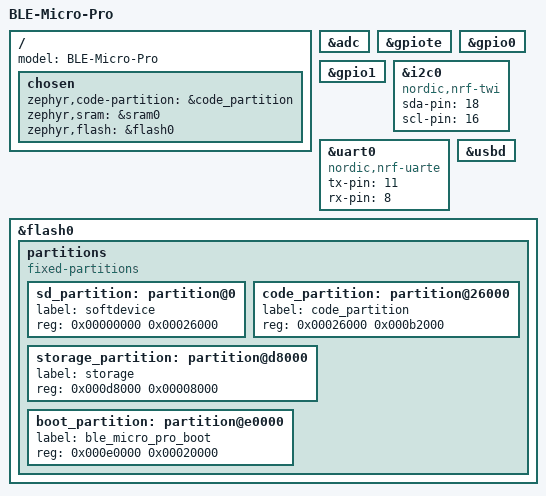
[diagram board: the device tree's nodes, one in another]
/*
 * Copyright (c) 2021 The ZMK Contributors
 *
 * SPDX-License-Identifier: MIT
 */

#include <nordic/nrf52840_qiaa.dtsi>
#include "arduino_pro_micro_pins.dtsi"

/ {
        model = "BLE-Micro-Pro";

        chosen {
                zephyr,code-partition = &code_partition;
                zephyr,sram = &sram0;
                zephyr,flash = &flash0;
        };
};

&adc {
        status = "okay";
};

&gpiote {
        status = "okay";
};

&gpio0 {
        status = "okay";
};

&gpio1 {
        status = "okay";
};

&i2c0 {
        compatible = "nordic,nrf-twi";
        sda-pin = <18>;
        scl-pin = <16>;
};

&uart0 {
        compatible = "nordic,nrf-uarte";
        tx-pin = <11>;
        rx-pin = <8>;
};

&usbd {
        status = "okay";
};

&flash0 {
        /*
         * For more information, see:
         * http://docs.zephyrproject.org/latest/devices/dts/flash_partitions.html
         */
        partitions {
                compatible = "fixed-partitions";
                #address-cells = <1>;
                #size-cells = <1>;

                sd_partition: partition@0 {
                        label = "softdevice";
                        reg = <0x00000000 0x00026000>;
                };
                code_partition: partition@26000 {
                        label = "code_partition";
                        reg = <0x00026000 0x000b2000>;
                };

                /*
                 * The flash starting at 0x000ec000 and ending at
                 * 0x000f3fff is reserved for use by the application.
                 */

                /*
                 * Storage partition will be used by FCB/LittleFS/NVS
                 * if enabled.
                 */
                storage_partition: partition@d8000 {
                        label = "storage";
                        reg = <0x000d8000 0x00008000>;
                };

                boot_partition: partition@e0000 {
                        label = "ble_micro_pro_boot";
                        reg = <0x000e0000 0x00020000>;
                };
        };
};
